AUTOSAR XML (schema 4-2-2)
package /ComponentTypes
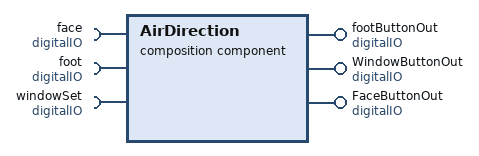
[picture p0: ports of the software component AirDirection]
  composition sw component type AirDirection
    require port face: required-interface=digitalIO
    require port foot: required-interface=digitalIO
    require port windowSet: required-interface=digitalIO
    provide port footButtonOut: provided-interface=digitalIO
    provide port WindowButtonOut: provided-interface=digitalIO
    provide port FaceButtonOut: provided-interface=digitalIO
    component FaceFootVent: type=FaceFootVentController
    delegate FaceFootVent.window <-> outer port windowSet
    delegate FaceFootVent.foot <-> outer port foot
    delegate FaceFootVent.face <-> outer port face
    delegate FaceFootVent.faceOut <-> outer port FaceButtonOut
    delegate FaceFootVent.windowOut <-> outer port WindowButtonOut
    delegate FaceFootVent.footOut <-> outer port footButtonOut
